VERSION ""

NS_ :

BS_:

BU_: VPU IHM BMS

BO_ 3221225472 VECTOR__INDEPENDENT_SIG_MSG: 0 Vector__XXX
 SG_ PAYLOAD_3 : 56|8@1+ (1,0) [0|0] "" Vector__XXX
 SG_ NewSignal_0002 : 16|8@1+ (1,0) [0|0] "" Vector__XXX

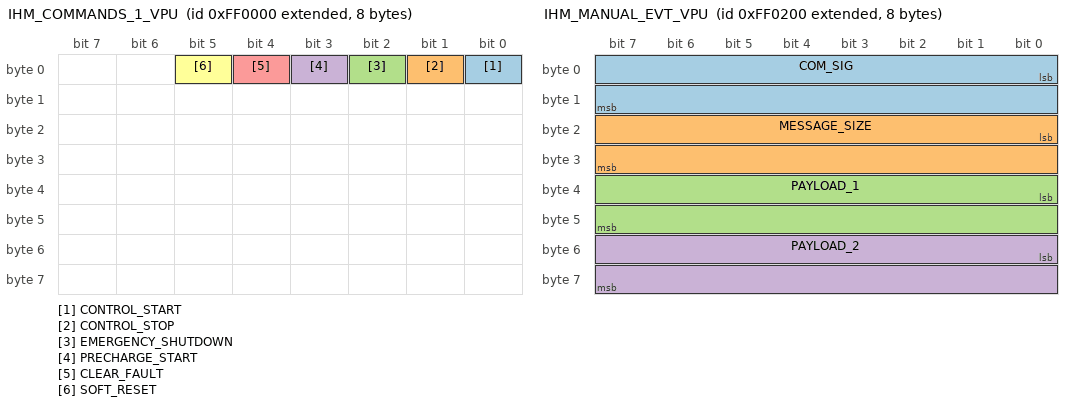
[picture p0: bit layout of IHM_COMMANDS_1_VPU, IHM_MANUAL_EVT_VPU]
BO_ 2164195328 IHM_COMMANDS_1_VPU: 8 IHM
 SG_ CONTROL_START : 0|1@1+ (1,0) [0|1] ""  VPU
 SG_ CONTROL_STOP : 1|1@1+ (1,0) [0|1] ""  VPU
 SG_ EMERGENCY_SHUTDOWN : 2|1@1+ (1,0) [0|1] ""  VPU
 SG_ PRECHARGE_START : 3|1@1+ (1,0) [0|1] "" Vector__XXX
 SG_ CLEAR_FAULT : 4|1@1+ (1,0) [0|1] "" Vector__XXX
 SG_ SOFT_RESET : 5|1@1+ (1,0) [0|1] "" Vector__XXX

BO_ 2164195584 IHM_SETPOINTS_1_VPU: 8 IHM
 SG_ SETPOINT_ID : 0|16@1+ (1,0) [0|65535] ""  VPU
 SG_ SETPOINT_REQUESTED : 16|16@1+ (0.01,0) [0|100] ""  VPU

BO_ 2164195840 IHM_MANUAL_EVT_VPU: 8 IHM
 SG_ COM_SIG : 0|16@1+ (1,0) [0|65535] ""  VPU
 SG_ MESSAGE_SIZE : 16|16@1+ (1,0) [0|2] ""  VPU
 SG_ PAYLOAD_1 : 32|16@1+ (1,0) [0|65535] ""  VPU
 SG_ PAYLOAD_2 : 48|16@1+ (1,0) [0|65535] ""  VPU

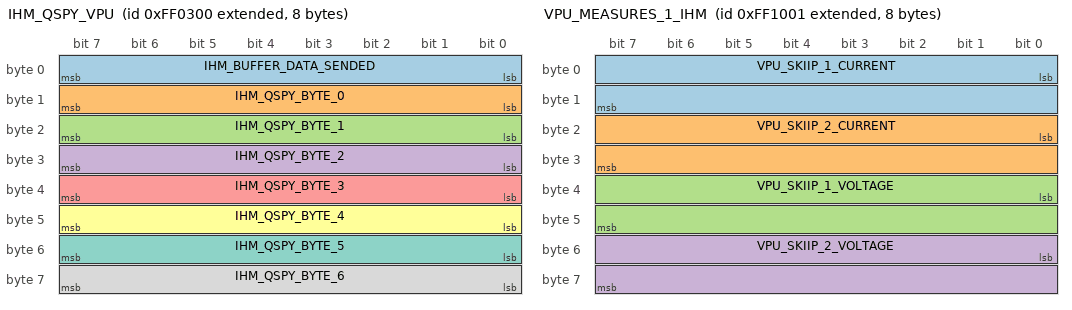
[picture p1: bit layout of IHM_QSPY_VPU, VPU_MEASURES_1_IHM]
BO_ 2164196096 IHM_QSPY_VPU: 8 IHM
 SG_ IHM_BUFFER_DATA_SENDED : 0|8@1+ (1,0) [1|7] ""  VPU
 SG_ IHM_QSPY_BYTE_0 : 8|8@1+ (1,0) [0|255] ""  VPU
 SG_ IHM_QSPY_BYTE_1 : 16|8@1+ (1,0) [0|255] ""  VPU
 SG_ IHM_QSPY_BYTE_2 : 24|8@1+ (1,0) [0|255] ""  VPU
 SG_ IHM_QSPY_BYTE_3 : 32|8@1+ (1,0) [0|255] ""  VPU
 SG_ IHM_QSPY_BYTE_4 : 40|8@1+ (1,0) [0|255] ""  VPU
 SG_ IHM_QSPY_BYTE_5 : 48|8@1+ (1,0) [0|255] ""  VPU
 SG_ IHM_QSPY_BYTE_6 : 56|8@1+ (1,0) [0|255] ""  VPU

BO_ 2164199425 VPU_MEASURES_1_IHM: 8 VPU
 SG_ VPU_SKIIP_1_CURRENT : 0|16@1+ (1,0) [0|3000] "" Vector__XXX
 SG_ VPU_SKIIP_2_CURRENT : 16|16@1+ (1,0) [0|3000] "" Vector__XXX
 SG_ VPU_SKIIP_1_VOLTAGE : 32|16@1+ (1,0) [0|2000] "" Vector__XXX
 SG_ VPU_SKIIP_2_VOLTAGE : 48|16@1+ (1,0) [0|2000] "" Vector__XXX

BO_ 2164199681 VPU_MEASURES_2_IHM: 8 VPU

BO_ 2164199937 VPU_SETPOINTS_1_IHM: 8 VPU
 SG_ VPU_IND_FSBB_CURRENT_SP : 0|16@1+ (1,0) [0|2500] "" Vector__XXX
 SG_ VPU_FSSB_POWER_SP : 16|16@1+ (1,0) [0|2000] "" Vector__XXX

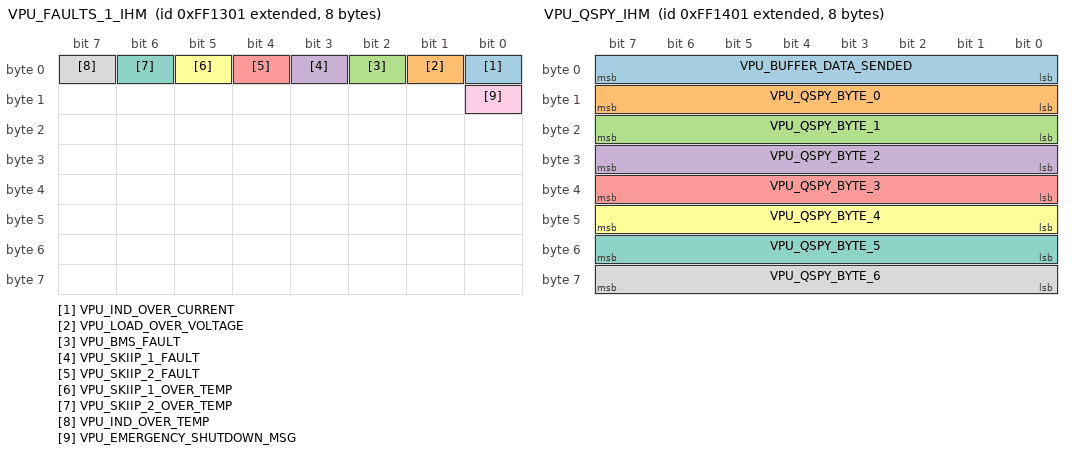
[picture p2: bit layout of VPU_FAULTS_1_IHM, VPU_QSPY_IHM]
BO_ 2164200193 VPU_FAULTS_1_IHM: 8 VPU
 SG_ VPU_IND_OVER_CURRENT : 0|1@1+ (1,0) [0|1] "" Vector__XXX
 SG_ VPU_LOAD_OVER_VOLTAGE : 1|1@1+ (1,0) [0|1] "" Vector__XXX
 SG_ VPU_BMS_FAULT : 2|1@1+ (1,0) [0|1] "" Vector__XXX
 SG_ VPU_SKIIP_1_FAULT : 3|1@1+ (1,0) [0|1] "" Vector__XXX
 SG_ VPU_SKIIP_2_FAULT : 4|1@1+ (1,0) [0|1] "" Vector__XXX
 SG_ VPU_SKIIP_1_OVER_TEMP : 5|1@1+ (1,0) [0|1] "" Vector__XXX
 SG_ VPU_SKIIP_2_OVER_TEMP : 6|1@1+ (1,0) [0|1] "" Vector__XXX
 SG_ VPU_IND_OVER_TEMP : 7|1@1+ (1,0) [0|1] "" Vector__XXX
 SG_ VPU_EMERGENCY_SHUTDOWN_MSG : 8|1@1+ (1,0) [0|1] "" Vector__XXX

BO_ 2164200449 VPU_QSPY_IHM: 8 VPU
 SG_ VPU_BUFFER_DATA_SENDED : 0|8@1+ (1,0) [1|7] "" Vector__XXX
 SG_ VPU_QSPY_BYTE_0 : 8|8@1+ (1,0) [0|255] "" Vector__XXX
 SG_ VPU_QSPY_BYTE_1 : 16|8@1+ (1,0) [0|255] "" Vector__XXX
 SG_ VPU_QSPY_BYTE_2 : 24|8@1+ (1,0) [0|255] "" Vector__XXX
 SG_ VPU_QSPY_BYTE_3 : 32|8@1+ (1,0) [0|255] "" Vector__XXX
 SG_ VPU_QSPY_BYTE_4 : 40|8@1+ (1,0) [0|255] "" Vector__XXX
 SG_ VPU_QSPY_BYTE_5 : 48|8@1+ (1,0) [0|255] "" Vector__XXX
 SG_ VPU_QSPY_BYTE_6 : 56|8@1+ (1,0) [0|255] "" Vector__XXX

CM_ BU_ VPU "Vehicle Propulsion Unit";
CM_ BU_ IHM "Human Machine Interface";
CM_ BU_ BMS "Battery Management System";
BA_DEF_ BU_  "NmStationAddress" INT 0 255;
BA_DEF_  "BusType" STRING ;
BA_DEF_  "ProtocolType" STRING ;
BA_DEF_ BO_  "VFrameFormat" ENUM  "StandardCAN","ExtendedCAN","reserved","J1939PG";
BA_DEF_DEF_  "NmStationAddress" 254;
BA_DEF_DEF_  "BusType" "CAN";
BA_DEF_DEF_  "ProtocolType" "J1939";
BA_DEF_DEF_  "VFrameFormat" "J1939PG";
VAL_ 2164195328 CONTROL_START 0 "NO" 1 "YES" ;
VAL_ 2164195328 CONTROL_STOP 0 "NO" 1 "YES" ;
VAL_ 2164195328 EMERGENCY_SHUTDOWN 0 "NO" 1 "YES" ;
VAL_ 2164195328 PRECHARGE_START 0 "NO" 1 "YES" ;
VAL_ 2164195328 CLEAR_FAULT 0 "NO" 1 "YES" ;
VAL_ 2164195328 SOFT_RESET 0 "NO" 1 "YES" ;
